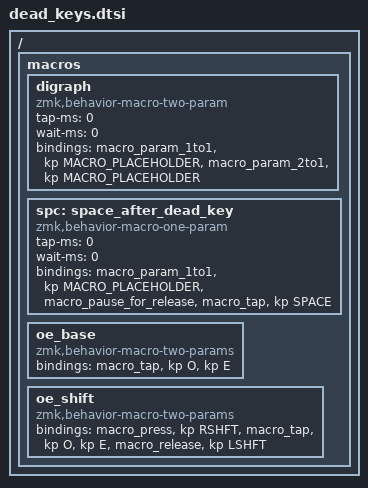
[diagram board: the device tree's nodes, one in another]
#include <behaviors.dtsi>
#include <dt-bindings/zmk/keys.h>

// Define a two-level key (e.g. punctuation key)
#define TWO_LEVEL_KEY(name, base, shift) name: name { \
  compatible = "zmk,behavior-mod-morph";              \
  #binding-cells = <0>;                               \
  bindings = <base>, <shift>;                         \
  mods = <(MOD_LSFT|MOD_RSFT)>;                       \
};

// Define a dead key
// note: macro_pause_for_release might be useless
#define DEAD_KEY(name, key) name: name {       \
  compatible = "zmk,behavior-macro-one-param"; \
  #binding-cells = <1>;                        \
  tap-ms = <0>;                                \
  wait-ms = <0>;                               \
  bindings                                     \
    = <&macro_tap key>                         \
    , <&macro_pause_for_release>               \
    , <&macro_param_1to1>                      \
    , <&kp MACRO_PLACEHOLDER>                  \
    ;                                          \
};

// Define a shifted dead key
// note: macro_pause_for_release might be useless
#define DEAD_KEY_SHIFT(name, key) name: name { \
  compatible = "zmk,behavior-macro-one-param"; \
  #binding-cells = <1>;                        \
  tap-ms = <0>;                                \
  wait-ms = <0>;                               \
  bindings                                     \
    = <&macro_tap key>                         \
    , <&macro_pause_for_release>               \
    , <&macro_press &kp LSHIFT>                \
    , <&macro_param_1to1>                      \
    , <&kp MACRO_PLACEHOLDER>                  \
    , <&macro_release &kp LSHIFT>              \
    ;                                          \
};

/ {
  macros {
    digraph: digraph {
      compatible = "zmk,behavior-macro-two-param";
      #binding-cells = <2>;
      tap-ms = <0>;
      wait-ms = <0>;
      bindings = <
        &macro_param_1to1 &kp MACRO_PLACEHOLDER
        &macro_param_2to1 &kp MACRO_PLACEHOLDER>;
    };

    spc: space_after_dead_key {
      compatible = "zmk,behavior-macro-one-param";
      #binding-cells = <1>;
      tap-ms = <0>;
      wait-ms = <0>;
      bindings
        = <&macro_param_1to1>
        , <&kp MACRO_PLACEHOLDER>
        , <&macro_pause_for_release>
        , <&macro_tap &kp SPACE>
        ;
    };
    oe_base: oe_base {
      compatible = "zmk,behavior-macro-two-params";
      #binding-cells = <2>;
      bindings = <&macro_tap &kp O &kp E>;
    };

    oe_shift: oe_shift {
      compatible = "zmk,behavior-macro-two-params";
      #binding-cells = <2>;
      bindings
        = <&macro_press &kp RSHFT>
        , <&macro_tap &kp O &kp E>
        , <&macro_release &kp LSHFT>
        ;
    };
  };
};
